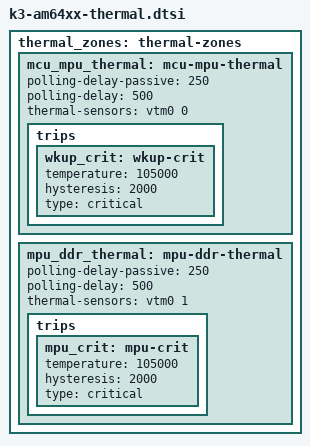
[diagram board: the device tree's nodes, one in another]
// SPDX-License-Identifier: GPL-2.0

#include <dt-bindings/thermal/thermal.h>

thermal_zones: thermal-zones {
	mcu_mpu_thermal: mcu-mpu-thermal {
		polling-delay-passive = <250>; /* milliseconds */
		polling-delay = <500>; /* milliseconds */
		thermal-sensors = <&vtm0 0>;

		trips {
			wkup_crit: wkup-crit {
				temperature = <105000>; /* milliCelsius */
				hysteresis = <2000>; /* milliCelsius */
				type = "critical";
			};
		};
	};

	mpu_ddr_thermal: mpu-ddr-thermal {
		polling-delay-passive = <250>; /* milliseconds */
		polling-delay = <500>; /* milliseconds */
		thermal-sensors = <&vtm0 1>;

		trips {
			mpu_crit: mpu-crit {
				temperature = <105000>; /* milliCelsius */
				hysteresis = <2000>; /* milliCelsius */
				type = "critical";
			};
		};
	};
};


